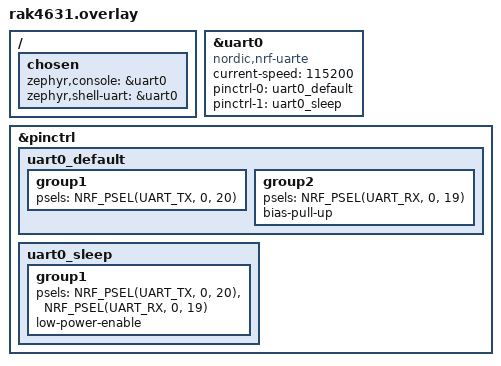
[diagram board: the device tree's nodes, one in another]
/*
 * LoRa basic test - Gateway (Tower)
 * Console: RAK_UART1 (P0.20 TX / P0.19 RX) → ttyUSB1
 */

/ {
	chosen {
		zephyr,console = &uart0;
		zephyr,shell-uart = &uart0;
	};
};

&uart0 {
	compatible = "nordic,nrf-uarte";
	status = "okay";
	current-speed = <115200>;
	pinctrl-0 = <&uart0_default>;
	pinctrl-1 = <&uart0_sleep>;
	pinctrl-names = "default", "sleep";
};

&pinctrl {
	uart0_default: uart0_default {
		group1 {
			psels = <NRF_PSEL(UART_TX, 0, 20)>;
		};
		group2 {
			psels = <NRF_PSEL(UART_RX, 0, 19)>;
			bias-pull-up;
		};
	};

	uart0_sleep: uart0_sleep {
		group1 {
			psels = <NRF_PSEL(UART_TX, 0, 20)>,
				<NRF_PSEL(UART_RX, 0, 19)>;
			low-power-enable;
		};
	};
};
